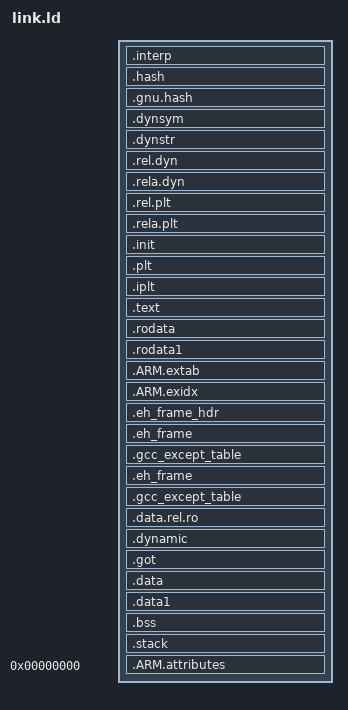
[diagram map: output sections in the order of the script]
OUTPUT_ARCH(arm)
ENTRY(_start)
SEARCH_DIR("=/usr/local/lib"); SEARCH_DIR("=/lib"); SEARCH_DIR("=/usr/lib");
SECTIONS
{
  /* Read-only sections, merged into text segment: */
  .interp         : { *(.interp) }
  .hash           : { *(.hash) }
  .gnu.hash       : { *(.gnu.hash) }
  .dynsym         : { *(.dynsym) }
  .dynstr         : { *(.dynstr) }
  .rel.dyn        :
    {
      *(.rel.init)
      *(.rel.text .rel.text.* .rel.gnu.linkonce.t.*)
      *(.rel.fini)
      *(.rel.rodata .rel.rodata.* .rel.gnu.linkonce.r.*)
      *(.rel.data.rel.ro* .rel.gnu.linkonce.d.rel.ro.*)
      *(.rel.data .rel.data.* .rel.gnu.linkonce.d.*)
      *(.rel.tdata .rel.tdata.* .rel.gnu.linkonce.td.*)
      *(.rel.tbss .rel.tbss.* .rel.gnu.linkonce.tb.*)
      *(.rel.ctors)
      *(.rel.dtors)
      *(.rel.got)
      *(.rel.bss .rel.bss.* .rel.gnu.linkonce.b.*)
      PROVIDE_HIDDEN (__rel_iplt_start = .);
      *(.rel.iplt)
      PROVIDE_HIDDEN (__rel_iplt_end = .);
      PROVIDE_HIDDEN (__rela_iplt_start = .);
      PROVIDE_HIDDEN (__rela_iplt_end = .);
    }
  .rela.dyn       :
    {
      *(.rela.init)
      *(.rela.text .rela.text.* .rela.gnu.linkonce.t.*)
      *(.rela.fini)
      *(.rela.rodata .rela.rodata.* .rela.gnu.linkonce.r.*)
      *(.rela.data .rela.data.* .rela.gnu.linkonce.d.*)
      *(.rela.tdata .rela.tdata.* .rela.gnu.linkonce.td.*)
      *(.rela.tbss .rela.tbss.* .rela.gnu.linkonce.tb.*)
      *(.rela.ctors)
      *(.rela.dtors)
      *(.rela.got)
      *(.rela.bss .rela.bss.* .rela.gnu.linkonce.b.*)
      PROVIDE_HIDDEN (__rel_iplt_start = .);
      PROVIDE_HIDDEN (__rel_iplt_end = .);
      PROVIDE_HIDDEN (__rela_iplt_start = .);
      *(.rela.iplt)
      PROVIDE_HIDDEN (__rela_iplt_end = .);
    }
  .rel.plt        :
    {
      *(.rel.plt)
    }
  .rela.plt       :
    {
      *(.rela.plt)
    }
  .init           :
  {
    KEEP (*(.init))
  } =0
  .plt            : { *(.plt) }
  .iplt           : { *(.iplt) }
  .text           :
  {
    *(.text.unlikely .text.*_unlikely)
    *(.text.exit .text.exit.*)
    *(.text.startup .text.startup.*)
    *(.text.hot .text.hot.*)
    *(.text .stub .text.* .gnu.linkonce.t.*)
    /* .gnu.warning sections are handled specially by elf32.em.  */
    *(.gnu.warning)
    *(.glue_7t) *(.glue_7) *(.vfp11_veneer) *(.v4_bx)
  } =0
  PROVIDE (__etext = .);
  PROVIDE (_etext = .);
  PROVIDE (etext = .);
  .rodata         : { *(.rodata .rodata.* .gnu.linkonce.r.*) }
  .rodata1        : { *(.rodata1) }
  .ARM.extab   : { *(.ARM.extab* .gnu.linkonce.armextab.*) }
   PROVIDE_HIDDEN (__exidx_start = .);
  .ARM.exidx   : { *(.ARM.exidx* .gnu.linkonce.armexidx.*) }
   PROVIDE_HIDDEN (__exidx_end = .);
  .eh_frame_hdr : { *(.eh_frame_hdr) }
  .eh_frame       : ONLY_IF_RO { KEEP (*(.eh_frame)) }
  .gcc_except_table   : ONLY_IF_RO { *(.gcc_except_table .gcc_except_table.*) }
  /* Adjust the address for the data segment.  We want to adjust up to
     the same address within the page on the next page up.  */
  . = ALIGN(CONSTANT (MAXPAGESIZE)) + (. & (CONSTANT (MAXPAGESIZE) - 1));
  /* Exception handling  */
  .eh_frame       : ONLY_IF_RW { KEEP (*(.eh_frame)) }
  .gcc_except_table   : ONLY_IF_RW { *(.gcc_except_table .gcc_except_table.*) }
  .data.rel.ro : { *(.data.rel.ro.local* .gnu.linkonce.d.rel.ro.local.*) *(.data.rel.ro* .gnu.linkonce.d.rel.ro.*) }
  .dynamic        : { *(.dynamic) }
  .got            : { *(.got.plt) *(.igot.plt) *(.got) *(.igot) }
  .data           :
  {
    __data_start = . ;
    *(.data .data.* .gnu.linkonce.d.*)
    SORT(CONSTRUCTORS)
  }
  .data1          : { *(.data1) }
  _edata = .; PROVIDE (edata = .);
  __bss_start = .;
  __bss_start__ = .;
  .bss            :
  {
   *(.dynbss)
   *(.bss .bss.* .gnu.linkonce.b.*)
   *(COMMON)
   /* Align here to ensure that the .bss section occupies space up to
      _end.  Align after .bss to ensure correct alignment even if the
      .bss section disappears because there are no input sections.
      FIXME: Why do we need it? When there is no .bss section, we don't
      pad the .data section.  */
   . = ALIGN(. != 0 ? 32 / 8 : 1);
  }
  _bss_end__ = . ; __bss_end__ = . ;
  . = ALIGN(32 / 8);
  . = ALIGN(32 / 8);
  __end__ = . ;
  _end = .; PROVIDE (end = .);

  .stack         :
  {
    _stack = .;
    *(.stack)
  }
  .ARM.attributes 0 : { KEEP (*(.ARM.attributes)) KEEP (*(.gnu.attributes)) }
  /DISCARD/ : { *(.note.GNU-stack) *(.gnu_debuglink) *(.gnu.lto_*) }
}

